# iostr730 register map
Registers are 16-bit, access not given, no defined reset value unless marked. A register's access mark holds for its fields unless they carry their own. Addresses are absolute; registers are grouped by the start of their names; [hi:lo] are bit positions; {n}, {i} and the like mark numbered series; 'fields as' and 'values as' point back to an identical list.

## WIU
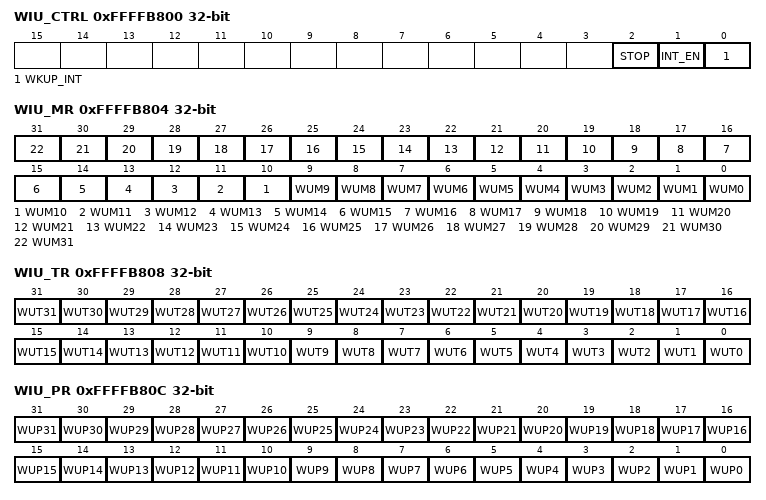
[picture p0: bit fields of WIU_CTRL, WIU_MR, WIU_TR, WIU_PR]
0xFFFFB800 WIU_CTRL 32-bit
  [2] STOP, [1] INT_EN, [0] WKUP_INT
0xFFFFB804 WIU_MR 32-bit
  [n] WUM{n} (n=0..31)
0xFFFFB808 WIU_TR 32-bit
  [n] WUT{n} (n=0..31)
0xFFFFB80C WIU_PR 32-bit
  [n] WUP{n} (n=0..31)
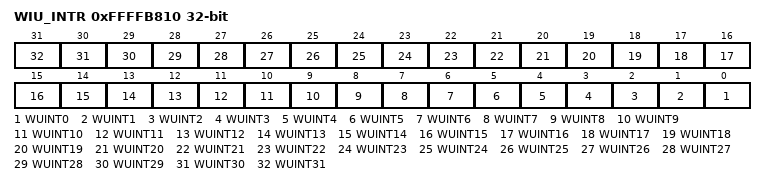
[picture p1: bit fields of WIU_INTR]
0xFFFFB810 WIU_INTR 32-bit
  [n] WUINT{n} (n=0..31)

## APB1
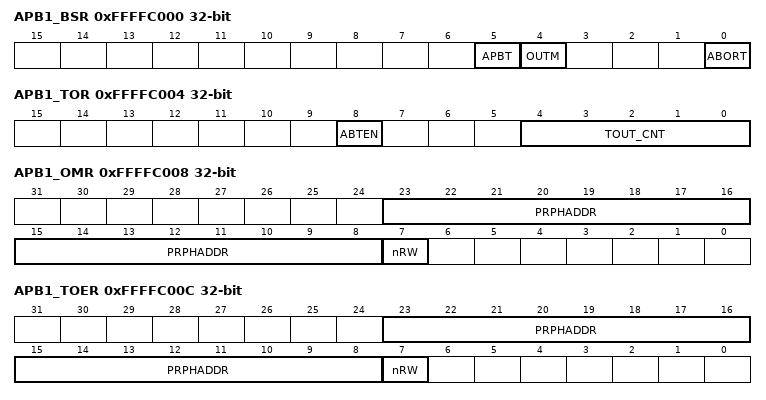
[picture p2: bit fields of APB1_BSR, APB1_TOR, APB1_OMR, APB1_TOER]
0xFFFFC000 APB1_BSR 32-bit
  [5] APBT, [4] OUTM, [0] ABORT
0xFFFFC004 APB1_TOR 32-bit
  [8] ABTEN, [4:0] TOUT_CNT
0xFFFFC008 APB1_OMR 32-bit
  [23:8] PRPHADDR, [7] nRW
0xFFFFC00C APB1_TOER 32-bit
  [23:8] PRPHADDR, [7] nRW

## CAN0
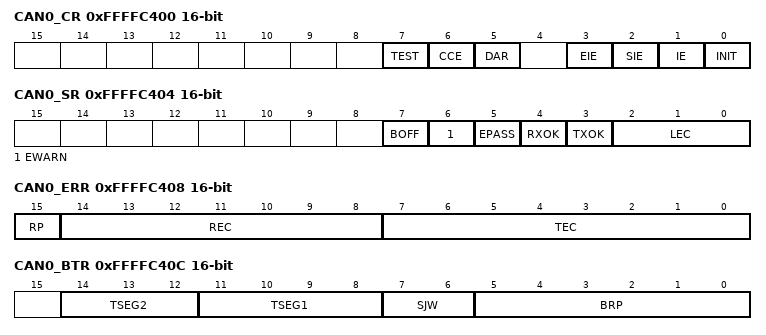
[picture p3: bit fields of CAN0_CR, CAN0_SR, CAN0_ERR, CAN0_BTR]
0xFFFFC400 CAN0_CR
  [7] TEST, [6] CCE, [5] DAR, [3] EIE, [2] SIE, [1] IE, [0] INIT
0xFFFFC404 CAN0_SR
  [7] BOFF, [6] EWARN, [5] EPASS, [4] RXOK, [3] TXOK, [2:0] LEC
0xFFFFC408 CAN0_ERR
  [15] RP, [14:8] REC, [7:0] TEC
0xFFFFC40C CAN0_BTR
  [14:12] TSEG2, [11:8] TSEG1, [7:6] SJW, [5:0] BRP
0xFFFFC410 CAN0_IDR
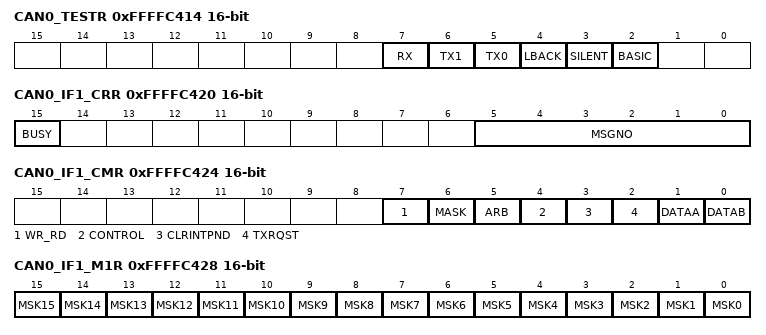
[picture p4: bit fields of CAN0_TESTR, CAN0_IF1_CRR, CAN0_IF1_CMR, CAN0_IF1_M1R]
0xFFFFC414 CAN0_TESTR
  [7] RX, [6] TX1, [5] TX0, [4] LBACK, [3] SILENT, [2] BASIC
0xFFFFC418 CAN0_BRPR
  [3:0] BRPE
0xFFFFC420 CAN0_IF1_CRR
  [15] BUSY, [5:0] MSGNO
0xFFFFC424 CAN0_IF1_CMR
  [7] WR_RD, [6] MASK, [5] ARB, [4] CONTROL, [3] CLRINTPND, [2] TXRQST, [1] DATAA, [0] DATAB
0xFFFFC428 CAN0_IF1_M1R
  [n] MSK{n} (n=0..15)
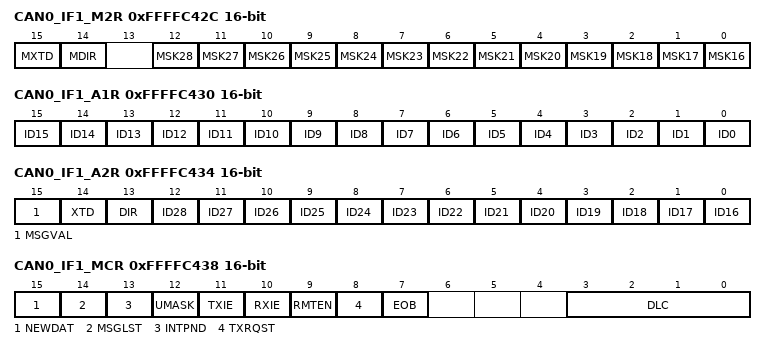
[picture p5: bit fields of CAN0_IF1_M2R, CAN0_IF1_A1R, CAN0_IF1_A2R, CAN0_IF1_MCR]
0xFFFFC42C CAN0_IF1_M2R
  [15] MXTD, [14] MDIR, [n-16] MSK{n} (n=16..28)
0xFFFFC430 CAN0_IF1_A1R
  [n] ID{n} (n=0..15)
0xFFFFC434 CAN0_IF1_A2R
  [15] MSGVAL, [14] XTD, [13] DIR, [n-16] ID{n} (n=16..28)
0xFFFFC438 CAN0_IF1_MCR
  [15] NEWDAT, [14] MSGLST, [13] INTPND, [12] UMASK, [11] TXIE, [10] RXIE, [9] RMTEN, [8] TXRQST, [7] EOB, [3:0] DLC
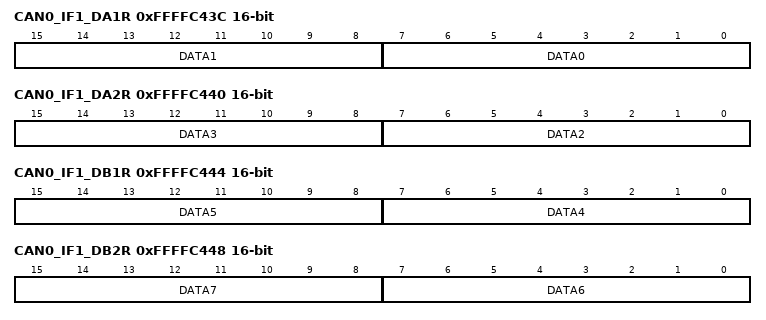
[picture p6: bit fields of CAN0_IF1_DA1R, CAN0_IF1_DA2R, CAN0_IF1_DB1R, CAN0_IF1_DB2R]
0xFFFFC43C CAN0_IF1_DA1R
  [15:8] DATA1, [7:0] DATA0
0xFFFFC440 CAN0_IF1_DA2R
  [15:8] DATA3, [7:0] DATA2
0xFFFFC444 CAN0_IF1_DB1R
  [15:8] DATA5, [7:0] DATA4
0xFFFFC448 CAN0_IF1_DB2R
  [15:8] DATA7, [7:0] DATA6
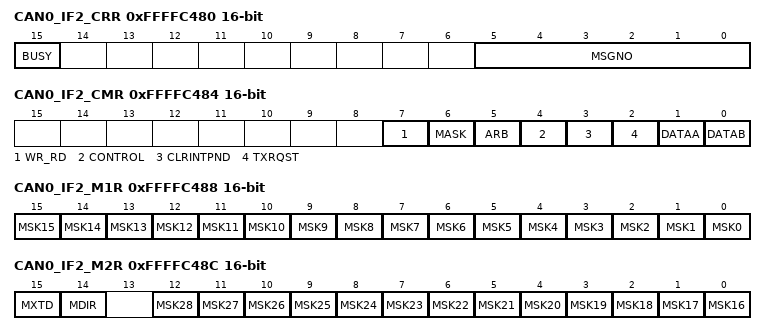
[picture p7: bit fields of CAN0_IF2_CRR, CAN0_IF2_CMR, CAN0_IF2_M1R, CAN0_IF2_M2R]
0xFFFFC480 CAN0_IF2_CRR
  [15] BUSY, [5:0] MSGNO
0xFFFFC484 CAN0_IF2_CMR
  fields as CAN0_IF1_CMR
0xFFFFC488 CAN0_IF2_M1R
  [n] MSK{n} (n=0..15)
0xFFFFC48C CAN0_IF2_M2R
  [15] MXTD, [14] MDIR, [n-16] MSK{n} (n=16..28)
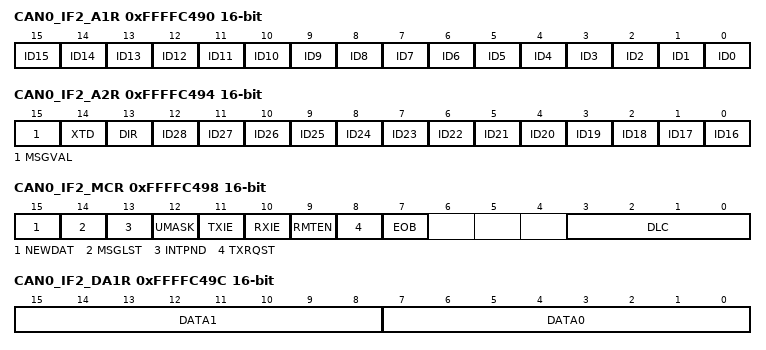
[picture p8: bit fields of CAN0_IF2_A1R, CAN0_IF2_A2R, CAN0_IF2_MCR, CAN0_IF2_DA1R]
0xFFFFC490 CAN0_IF2_A1R
  [n] ID{n} (n=0..15)
0xFFFFC494 CAN0_IF2_A2R
  [15] MSGVAL, [14] XTD, [13] DIR, [n-16] ID{n} (n=16..28)
0xFFFFC498 CAN0_IF2_MCR
  fields as CAN0_IF1_MCR
0xFFFFC49C CAN0_IF2_DA1R
  [15:8] DATA1, [7:0] DATA0
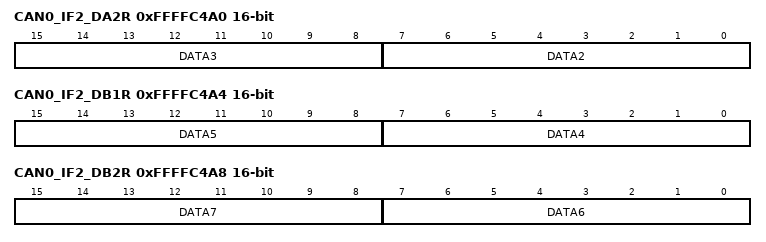
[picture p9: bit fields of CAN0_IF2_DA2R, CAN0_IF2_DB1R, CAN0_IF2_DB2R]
0xFFFFC4A0 CAN0_IF2_DA2R
  [15:8] DATA3, [7:0] DATA2
0xFFFFC4A4 CAN0_IF2_DB1R
  [15:8] DATA5, [7:0] DATA4
0xFFFFC4A8 CAN0_IF2_DB2R
  [15:8] DATA7, [7:0] DATA6
0xFFFFC500 CAN0_TXR1R 32-bit
0xFFFFC504 CAN0_TXR2R 32-bit
0xFFFFC520 CAN0_ND1R 32-bit
0xFFFFC524 CAN0_ND2R 32-bit
0xFFFFC540 CAN0_IP1R 32-bit
0xFFFFC544 CAN0_IP2R 32-bit
0xFFFFC560 CAN0_MV1R 32-bit
0xFFFFC564 CAN0_MV2R 32-bit

## CAN1
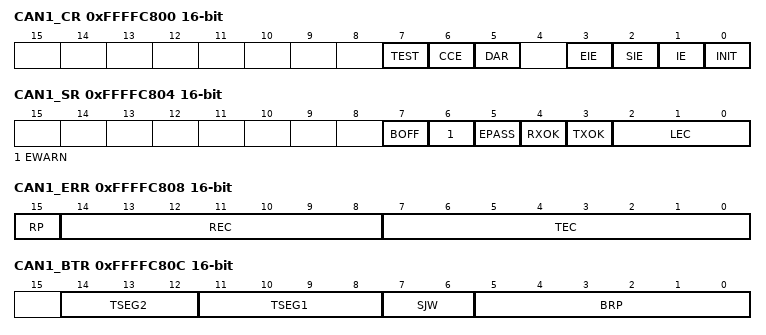
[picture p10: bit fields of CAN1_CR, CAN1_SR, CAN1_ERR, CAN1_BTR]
0xFFFFC800 CAN1_CR
  [7] TEST, [6] CCE, [5] DAR, [3] EIE, [2] SIE, [1] IE, [0] INIT
0xFFFFC804 CAN1_SR
  [7] BOFF, [6] EWARN, [5] EPASS, [4] RXOK, [3] TXOK, [2:0] LEC
0xFFFFC808 CAN1_ERR
  [15] RP, [14:8] REC, [7:0] TEC
0xFFFFC80C CAN1_BTR
  [14:12] TSEG2, [11:8] TSEG1, [7:6] SJW, [5:0] BRP
0xFFFFC810 CAN1_IDR
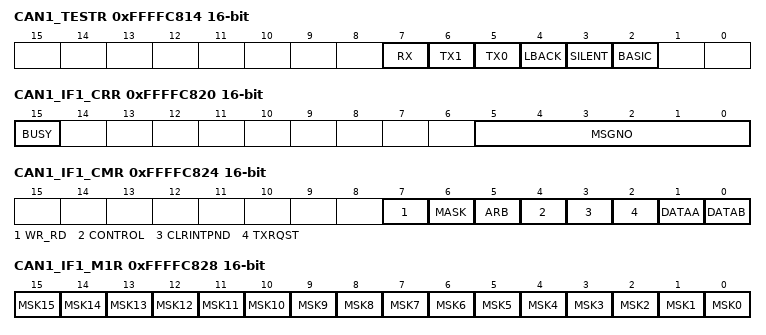
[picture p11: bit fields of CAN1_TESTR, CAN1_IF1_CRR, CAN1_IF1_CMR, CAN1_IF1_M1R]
0xFFFFC814 CAN1_TESTR
  [7] RX, [6] TX1, [5] TX0, [4] LBACK, [3] SILENT, [2] BASIC
0xFFFFC818 CAN1_BRPR
  [3:0] BRPE
0xFFFFC820 CAN1_IF1_CRR
  [15] BUSY, [5:0] MSGNO
0xFFFFC824 CAN1_IF1_CMR
  [7] WR_RD, [6] MASK, [5] ARB, [4] CONTROL, [3] CLRINTPND, [2] TXRQST, [1] DATAA, [0] DATAB
0xFFFFC828 CAN1_IF1_M1R
  [n] MSK{n} (n=0..15)
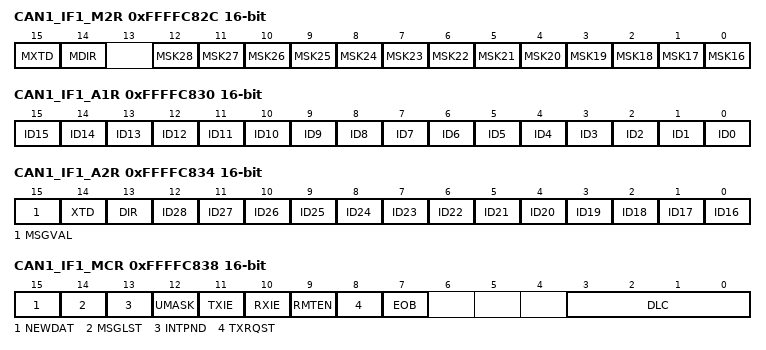
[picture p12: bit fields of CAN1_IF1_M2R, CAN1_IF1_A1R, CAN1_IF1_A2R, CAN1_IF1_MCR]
0xFFFFC82C CAN1_IF1_M2R
  [15] MXTD, [14] MDIR, [n-16] MSK{n} (n=16..28)
0xFFFFC830 CAN1_IF1_A1R
  [n] ID{n} (n=0..15)
0xFFFFC834 CAN1_IF1_A2R
  [15] MSGVAL, [14] XTD, [13] DIR, [n-16] ID{n} (n=16..28)
0xFFFFC838 CAN1_IF1_MCR
  [15] NEWDAT, [14] MSGLST, [13] INTPND, [12] UMASK, [11] TXIE, [10] RXIE, [9] RMTEN, [8] TXRQST, [7] EOB, [3:0] DLC
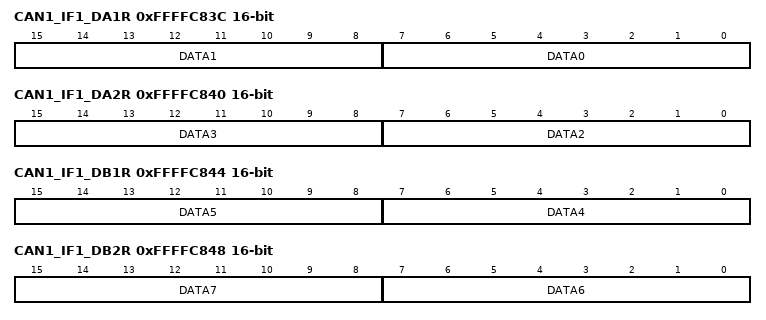
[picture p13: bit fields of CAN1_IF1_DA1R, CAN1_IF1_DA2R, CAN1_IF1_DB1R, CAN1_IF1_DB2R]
0xFFFFC83C CAN1_IF1_DA1R
  [15:8] DATA1, [7:0] DATA0
0xFFFFC840 CAN1_IF1_DA2R
  [15:8] DATA3, [7:0] DATA2
0xFFFFC844 CAN1_IF1_DB1R
  [15:8] DATA5, [7:0] DATA4
0xFFFFC848 CAN1_IF1_DB2R
  [15:8] DATA7, [7:0] DATA6
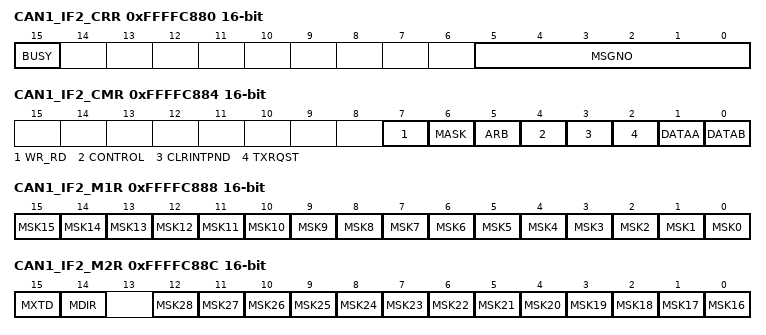
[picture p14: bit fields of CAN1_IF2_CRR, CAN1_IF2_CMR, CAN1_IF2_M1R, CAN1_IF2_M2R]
0xFFFFC880 CAN1_IF2_CRR
  [15] BUSY, [5:0] MSGNO
0xFFFFC884 CAN1_IF2_CMR
  fields as CAN1_IF1_CMR
0xFFFFC888 CAN1_IF2_M1R
  [n] MSK{n} (n=0..15)
0xFFFFC88C CAN1_IF2_M2R
  [15] MXTD, [14] MDIR, [n-16] MSK{n} (n=16..28)
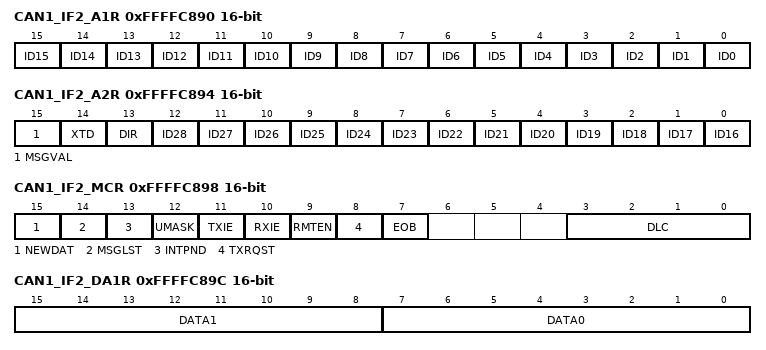
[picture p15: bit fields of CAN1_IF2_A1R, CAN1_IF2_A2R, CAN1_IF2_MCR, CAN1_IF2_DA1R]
0xFFFFC890 CAN1_IF2_A1R
  [n] ID{n} (n=0..15)
0xFFFFC894 CAN1_IF2_A2R
  [15] MSGVAL, [14] XTD, [13] DIR, [n-16] ID{n} (n=16..28)
0xFFFFC898 CAN1_IF2_MCR
  fields as CAN1_IF1_MCR
0xFFFFC89C CAN1_IF2_DA1R
  [15:8] DATA1, [7:0] DATA0
0xFFFFC8A0 CAN1_IF2_DA2R
  [15:8] DATA3, [7:0] DATA2
0xFFFFC8A4 CAN1_IF2_DB1R
  [15:8] DATA5, [7:0] DATA4
0xFFFFC8A8 CAN1_IF2_DB2R
  [15:8] DATA7, [7:0] DATA6
0xFFFFC900 CAN1_TXR1R 32-bit
0xFFFFC904 CAN1_TXR2R 32-bit
0xFFFFC920 CAN1_ND1R 32-bit
0xFFFFC924 CAN1_ND2R 32-bit
0xFFFFC940 CAN1_IP1R 32-bit
0xFFFFC944 CAN1_IP2R 32-bit
0xFFFFC960 CAN1_MV1R 32-bit
0xFFFFC964 CAN1_MV2R 32-bit
